# R7FA4W1AD register map
Vendor: Renesas; Series: RA4; File version: 1.0
CPU: CM4 r0p1, little endian, MPU, FPU, VTOR, 4 interrupt priority bits
Registers are 8-bit, read-write, reset 0x0 unless marked. A register's access mark holds for its fields unless they carry their own. Offsets are from the block's base; [hi:lo] are bit positions; {n}, {i} and the like mark numbered series.

## SYSTEM — System Control
Base 0x4001E000
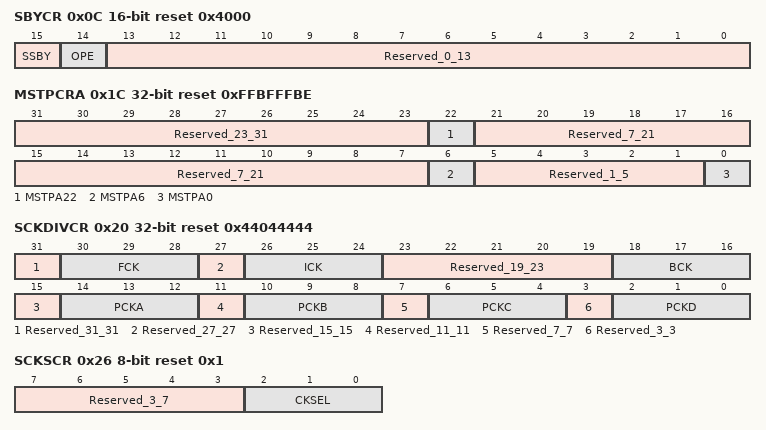
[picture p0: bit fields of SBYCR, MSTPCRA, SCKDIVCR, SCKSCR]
0x0C SBYCR 16-bit reset 0x4000 — Standby Control Register
  [15] SSBY — Software Standby
  [14] OPE — Output Port Enable
  [13:0] Reserved_0_13 — These bits are read as 00000000000000. The write value should be 00000000000000.
0x1C MSTPCRA 32-bit reset 0xFFBFFFBE — Module Stop Control Register A
  [31:23] Reserved_23_31 — These bits are read as 111111111. The write value should be 111111111.
  [22] MSTPA22 — DMA Controller/Data Transfer Controller Module Stop
  [21:7] Reserved_7_21 — These bits are read as 111111111111111. The write value should be 111111111111111.
  [6] MSTPA6 — ECCRAM Module Stop
  [5:1] Reserved_1_5 — These bits are read as 11111. The write value should be 11111.
  [0] MSTPA0 — RAM0 Module Stop
0x20 SCKDIVCR 32-bit reset 0x44044444 — System Clock Division Control Register
  [31] Reserved_31_31 — This bit is read as 0. The write value should be 0.
  [30:28] FCK — Flash IF Clock (FCLK) Select
  [27] Reserved_27_27 — This bit is read as 0. The write value should be 0.
  [26:24] ICK — System Clock (ICLK) Select
  [23:19] Reserved_19_23 — These bits are read as 00000. The write value should be 00000.
  [18:16] BCK — External Bus Clock (BCLK) Select
  [15] Reserved_15_15 — This bit is read as 0. The write value should be 0.
  [14:12] PCKA — Peripheral Module Clock A (PCLKA) Select
  [11] Reserved_11_11 — This bit is read as 0. The write value should be 0.
  [10:8] PCKB — Peripheral Module Clock B (PCLKB) Select
  [7] Reserved_7_7 — This bit is read as 0. The write value should be 0.
  [6:4] PCKC — Peripheral Module Clock C (PCLKC) Select
  [3] Reserved_3_3 — This bit is read as 0. The write value should be 0.
  [2:0] PCKD — Peripheral Module Clock D (PCLKD) Select
0x26 SCKSCR reset 0x1 — System Clock Source Control Register
  [7:3] Reserved_3_7 — These bits are read as 00000. The write value should be 00000.
  [2:0] CKSEL — Clock Source SelectSelecting the system clock source faster than 32MHz(system clock source > 32MHz ) is prohibit when SCKDIVCR.ICK[2:0] bits select the division,by-1 and MEMWAIT.MEMWAIT =0.
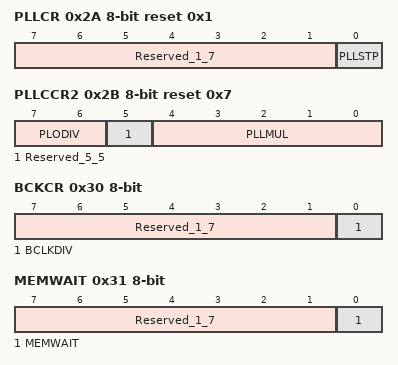
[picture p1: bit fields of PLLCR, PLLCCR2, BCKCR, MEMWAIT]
0x2A PLLCR reset 0x1 — PLL Control Register
  [7:1] Reserved_1_7 — These bits are read as 0000000. The write value should be 0000000.
  [0] PLLSTP — PLL Stop Control
0x2B PLLCCR2 reset 0x7 — PLL Clock Control Register2
  [7:6] PLODIV — PLL Output Frequency Division Ratio Select
  [5] Reserved_5_5 — This bit is read as 0. The write value should be 0.
  [4:0] PLLMUL — PLL Frequency Multiplication Factor Select
0x30 BCKCR — External Bus Clock Control Register
  [7:1] Reserved_1_7 — These bits are read as 0000000. The write value should be 0000000.
  [0] BCLKDIV — EBCLK Pin Output Select
0x31 MEMWAIT — Memory Wait Cycle Control Register
  [7:1] Reserved_1_7 — These bits are read as 0000000. The write value should be 0000000.
  [0] MEMWAIT — Memory Wait Cycle SelectNote: Writing 0 to the MEMWAIT is prohibited when SCKDIVCR.ICK selects division by 1 and SCKSCR.CKSEL[2:0] bits select thesystem clock source that is faster than 32 MHz (ICLK > 32 MHz).
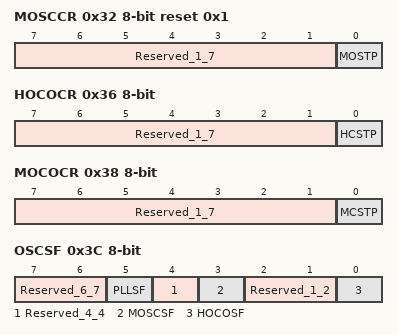
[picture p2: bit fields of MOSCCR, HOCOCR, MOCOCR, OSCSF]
0x32 MOSCCR reset 0x1 — Main Clock Oscillator Control Register
  [7:1] Reserved_1_7 — These bits are read as 0000000. The write value should be 0000000.
  [0] MOSTP — Main Clock Oscillator StopNote: MOMCR register must be set before setting MOSTP to 0.
0x36 HOCOCR (reset mask 0xFE) — High,Speed On,Chip Oscillator Control Register
  [7:1] Reserved_1_7 — These bits are read as 0000000. The write value should be 0000000.
  [0] HCSTP — HOCO Stop
0x38 MOCOCR — Middle,Speed On,Chip Oscillator Control Register
  [7:1] Reserved_1_7 — These bits are read as 0000000. The write value should be 0000000.
  [0] MCSTP — MOCO Stop
0x3C OSCSF ro (reset mask 0xFE) — Oscillation Stabilization Flag Register
  [7:6] Reserved_6_7 — These bits are read as 00.
  [5] PLLSF — PLL Clock Oscillation Stabilization Flag
  [4] Reserved_4_4 — This bit is read as 0.
  [3] MOSCSF — Main Clock Oscillation Stabilization Flag
  [2:1] Reserved_1_2 — These bits are read as 00.
  [0] HOCOSF — HOCO Clock Oscillation Stabilization FlagNOTE: The HOCOSF bit value after a reset is 1 when the OFS1.HOCOEN bit is 0. It is 0 when the OFS1.HOCOEN bit is 1.
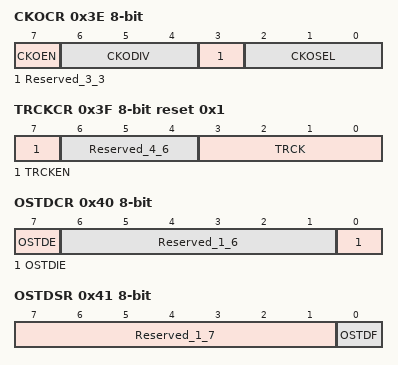
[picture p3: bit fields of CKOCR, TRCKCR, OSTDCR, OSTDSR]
0x3E CKOCR — Clock Out Control Register
  [7] CKOEN — Clock out enable
  [6:4] CKODIV — Clock out input frequency Division Select
  [3] Reserved_3_3 — This bit is read as 0. The write value should be 0.
  [2:0] CKOSEL — Clock out source select
0x3F TRCKCR reset 0x1 — Trace Clock Control Register
  [7] TRCKEN — Trace Clock operating enable
  [6:4] Reserved_4_6 — These bits are read as 000. The write value should be 000.
  [3:0] TRCK — Trace Clock operating frequency select
0x40 OSTDCR — Oscillation Stop Detection Control Register
  [7] OSTDE — Oscillation Stop Detection Function Enable
  [6:1] Reserved_1_6 — These bits are read as 000000. The write value should be 000000.
  [0] OSTDIE — Oscillation Stop Detection Interrupt Enable
0x41 OSTDSR — Oscillation Stop Detection Status Register
  [7:1] Reserved_1_7 — These bits are read as 0000000. The write value should be 0000000.
  [0] OSTDF write-0-clears read-modifies — Oscillation Stop Detection Flag
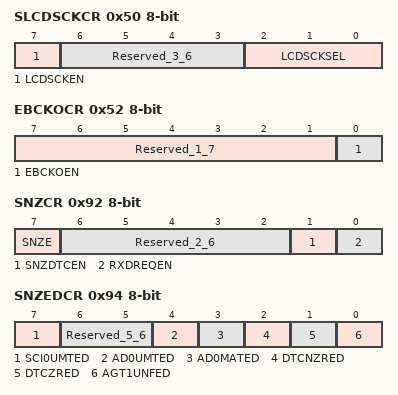
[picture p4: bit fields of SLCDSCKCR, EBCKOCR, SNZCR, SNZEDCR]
0x50 SLCDSCKCR — Segment LCD Source Clock Control Register
  [7] LCDSCKEN — LCD Source Clock Out Enable
  [6:3] Reserved_3_6 — These bits are read as 0000. The write value should be 0000.
  [2:0] LCDSCKSEL — LCD Source Clock (LCDSRCCLK) Select
0x52 EBCKOCR — External Bus Clock Output Control Register
  [7:1] Reserved_1_7 — These bits are read as 0000000. The write value should be 0000000.
  [0] EBCKOEN — EBCLK Pin Output Control
0x61 MOCOUTCR — MOCO User Trimming Control Register
  [7:0] MOCOUTRM — MOCO User Trimming 1000_0000 : -128 1000_0001 : -127 1000_0010 : -126 . . . 1111_1111 : -1 0000_0000 : Center Code 0000_0001 : +1 . . . 0111_1101 : +125 0111_1110 : +126 0111_1111 : +127These bits are added to original MOCO trimming bits
0x62 HOCOUTCR — HOCO User Trimming Control Register
  [7:0] HOCOUTRM — HOCO User Trimming 1000_0000 : -128 1000_0001 : -127 1000_0010 : -126 . . . 1111_1111 : -1 0000_0000 : Center Code 0000_0001 : +1 . . . 0111_1101 : +125 0111_1110 : +126 0111_1111 : +127These bits are added to original HOCO trimming bits
0x92 SNZCR — Snooze Control Register
  [7] SNZE — Snooze Mode Enable
  [6:2] Reserved_2_6 — These bits are read as 00000. The write value should be 00000.
  [1] SNZDTCEN — DTC Enable in Snooze Mode
  [0] RXDREQEN — RXD0 Snooze Request Enable NOTE: Do not set to 1 other than in asynchronous mode.
0x94 SNZEDCR — Snooze End Control Register
  [7] SCI0UMTED — SCI0 Address Mismatch Snooze End Enable
  [6:5] Reserved_5_6 — These bits are read as 00. The write value should be 00.
  [4] AD0UMTED — ADC140 Compare Mismatch Snooze End Enable
  [3] AD0MATED — ADC140 Compare Match Snooze End Enable
  [2] DTCNZRED — Not Last DTC Transmission Completion Snooze End Enable
  [1] DTCZRED — Last DTC Transmission Completion Snooze End Enable
  [0] AGT1UNFED — AGT1 Underflow Snooze End Enable
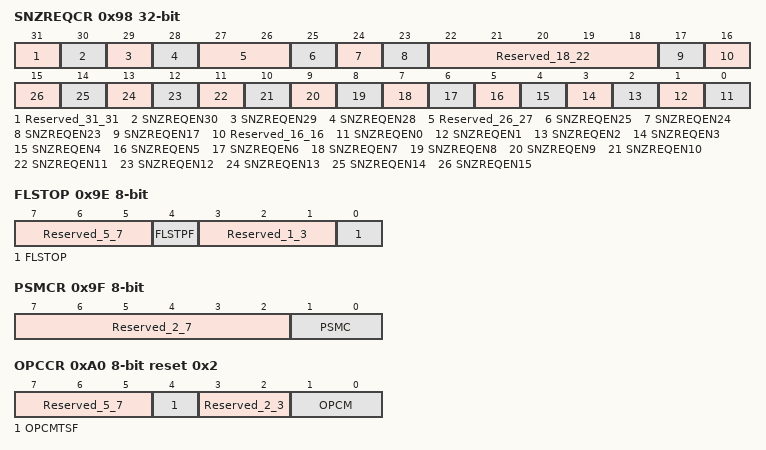
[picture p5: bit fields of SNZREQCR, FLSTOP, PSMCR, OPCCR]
0x98 SNZREQCR 32-bit — Snooze Request Control Register
  [31] Reserved_31_31 — This bit is read as 0. The write value should be 0.
  [30] SNZREQEN30 — Snooze Request Enable 30Enable AGT1 compare match B snooze request
  [29] SNZREQEN29 — Snooze Request Enable 29Enable AGT1 compare match A snooze request
  [28] SNZREQEN28 — Snooze Request Enable 28Enable AGT1 underflow snooze request
  [27:26] Reserved_26_27 — These bits are read as 00. The write value should be 00.
  [25] SNZREQEN25 — Snooze Request Enable 25Enable RTC period snooze request
  [24] SNZREQEN24 — Snooze Request Enable 24Enable RTC alarm snooze request
  [23] SNZREQEN23 — Snooze Request Enable 23Enable RTC alarm snooze request
  [22:18] Reserved_18_22 — These bits are read as 00000. The write value should be 00000.
  [17] SNZREQEN17 — Snooze Request Enable 17Enable KR snooze request
  [16] Reserved_16_16 — This bit is read as 0. The write value should be 0.
  [n] SNZREQEN{n} (n=0..15) — Snooze Request Enable {n}Enable IRQ{n} pin snooze request
0x9E FLSTOP — Flash Operation Control Register
  [7:5] Reserved_5_7 — These bits are read as 000. The write value should be 000.
  [4] FLSTPF — Flash Memory Operation Status Flag
  [3:1] Reserved_1_3 — These bits are read as 000. The write value should be 000.
  [0] FLSTOP — Selecting ON/OFF of the Flash Memory Operation
0x9F PSMCR — Power Save Memory Control Register
  [7:2] Reserved_2_7 — These bits are read as 000000. The write value should be 000000.
  [1:0] PSMC — Power save memory control.
0xA0 OPCCR reset 0x2 — Operating Power Control Register
  [7:5] Reserved_5_7 — These bits are read as 000. The write value should be 000.
  [4] OPCMTSF — Operating Power Control Mode Transition Status Flag
  [3:2] Reserved_2_3 — These bits are read as 00. The write value should be 00.
  [1:0] OPCM — Operating Power Control Mode Select
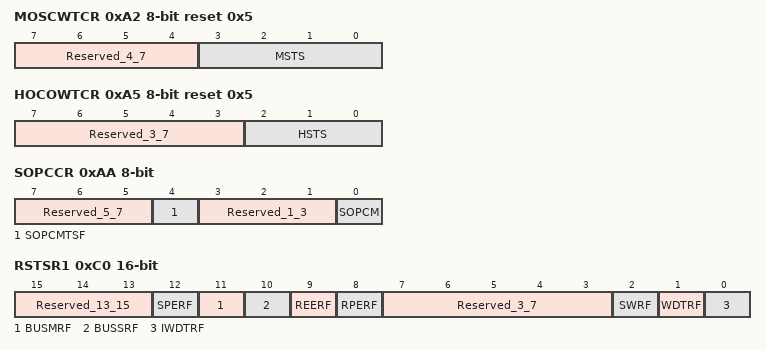
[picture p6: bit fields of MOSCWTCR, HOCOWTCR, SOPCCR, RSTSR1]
0xA2 MOSCWTCR reset 0x5 — Main Clock Oscillator Wait Control Register
  [7:4] Reserved_4_7 — These bits are read as 0000. The write value should be 0000.
  [3:0] MSTS — Main clock oscillator wait time setting
0xA5 HOCOWTCR reset 0x5 — High,Speed On,Chip Oscillator Wait Control Register
  [7:3] Reserved_3_7 — These bits are read as 00000. The write value should be 00000.
  [2:0] HSTS — HOCO wait time setting
0xAA SOPCCR — Sub Operating Power Control Register
  [7:5] Reserved_5_7 — These bits are read as 000. The write value should be 000.
  [4] SOPCMTSF ro — Sub Operating Power Control Mode Transition Status Flag
  [3:1] Reserved_1_3 — These bits are read as 000. The write value should be 000.
  [0] SOPCM — Sub Operating Power Control Mode Select
0xC0 RSTSR1 16-bit (reset mask 0xE0F8) — Reset Status Register 1
  [15:13] Reserved_13_15 — These bits are read as 000. The write value should be 000.
  [12] SPERF write-0-clears read-modifies — SP Error Reset Detect FlagNote: Only 0 can be written to clear the flag. The reset flag must be written as 0 after the reset flag is read as 1.
  [11] BUSMRF write-0-clears read-modifies — Bus Master MPU Reset Detect FlagNote: Only 0 can be written to clear the flag. The reset flag must be written as 0 after the reset flag is read as 1.
  [10] BUSSRF write-0-clears read-modifies — Bus Slave MPU Reset Detect FlagNote: Only 0 can be written to clear the flag. The reset flag must be written as 0 after the reset flag is read as 1.
  [9] REERF write-0-clears read-modifies — RAM ECC Error Reset Detect FlagNote: Only 0 can be written to clear the flag. The reset flag must be written as 0 after the reset flag is read as 1.
  [8] RPERF write-0-clears read-modifies — RAM Parity Error Reset Detect FlagNote: Only 0 can be written to clear the flag. The reset flag must be written as 0 after the reset flag is read as 1.
  [7:3] Reserved_3_7 — These bits are read as 00000. The write value should be 00000.
  [2] SWRF write-0-clears read-modifies — Software Reset Detect FlagNote: Only 0 can be written to clear the flag. The reset flag must be written as 0 after the reset flag is read as 1.
  [1] WDTRF write-0-clears read-modifies — Watchdog Timer Reset Detect FlagNote: Only 0 can be written to clear the flag. The reset flag must be written as 0 after the reset flag is read as 1.
  [0] IWDTRF write-0-clears read-modifies — Independent Watchdog Timer Reset Detect FlagNote: Only 0 can be written to clear the flag. The reset flag must be written as 0 after the reset flag is read as 1.
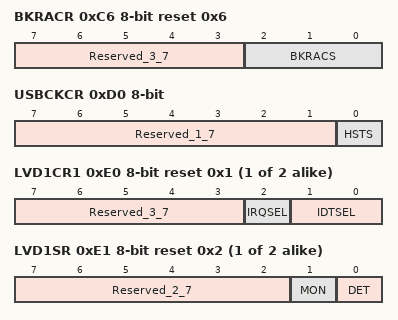
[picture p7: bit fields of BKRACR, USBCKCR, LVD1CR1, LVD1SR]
0xC6 BKRACR reset 0x6 — Backup Register Access Control Register
  [7:3] Reserved_3_7 — These bits are read as 00000. The write value should be 00000.
  [2:0] BKRACS — Backup Register Access Control Register
0xD0 USBCKCR — USB Clock Control register
  [7:1] Reserved_1_7 — These bits are read as 0000000. The write value should be 0000000.
  [0] HSTS — USB Clock Source Select
{0xDE+2i} LVD{i}CR1 (i=1..2) reset 0x1 — Voltage Monitor {i} Circuit Control Register 1
  [7:3] Reserved_3_7 — These bits are read as 00000. The write value should be 00000.
  [2] IRQSEL — Voltage Monitor Interrupt Type Select
  [1:0] IDTSEL — Voltage Monitor Interrupt Generation Condition Select
{0xDF+2i} LVD{i}SR (i=1..2) reset 0x2 — Voltage Monitor {i} Circuit Status Register
  [7:2] Reserved_2_7 — These bits are read as 000000. The write value should be 000000.
  [1] MON ro — Voltage Monitor 1 Signal Monitor Flag
  [0] DET write-0-clears read-modifies — Voltage Monitor Voltage Change Detection Flag NOTE: Only 0 can be written to this bit. After writing 0 to this bit, it takes 2 system clock cycles for the bit to be read as 0.
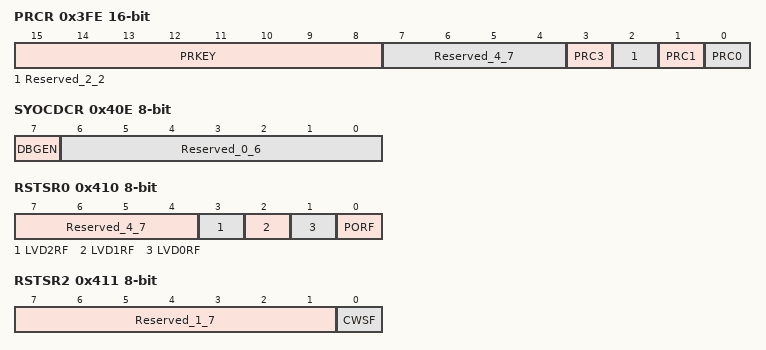
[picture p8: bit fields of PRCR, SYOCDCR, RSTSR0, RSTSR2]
0x3FE PRCR 16-bit — Protect Register
  [15:8] PRKEY wo — PRC Key Code
  [7:4] Reserved_4_7 — These bits are read as 0000. The write value should be 0000.
  [3] PRC3 — Protect Bit 3
  [2] Reserved_2_2 — This bit is read as 0. The write value should be 0.
  [1] PRC1 — Protect Bit 1
  [0] PRC0 — Protect Bit 0
0x40E SYOCDCR — System Control OCD Control Register
  [7] DBGEN — Debugger Enable bit
  [6:0] Reserved_0_6 — These bits are read as 0000000. The write value should be 0000000.
0x410 RSTSR0 (reset mask 0xF0) — Reset Status Register 0
  [7:4] Reserved_4_7 — These bits are read as 0000. The write value should be 0000.
  [3] LVD2RF write-0-clears read-modifies — Voltage Monitor 2 Reset Detect FlagNote: Only 0 can be written to clear the flag. The reset flag must be written with 0 after the reset flag is read as 1.
  [2] LVD1RF write-0-clears read-modifies — Voltage Monitor 1 Reset Detect FlagNote: Only 0 can be written to clear the flag. The reset flag must be written with 0 after the reset flag is read as 1.
  [1] LVD0RF write-0-clears read-modifies — Voltage Monitor 0 Reset Detect FlagNote: Only 0 can be written to clear the flag. The reset flag must be written with 0 after the reset flag is read as 1.
  [0] PORF write-0-clears read-modifies — Power,On Reset Detect FlagNote: Only 0 can be written to clear the flag. The reset flag must be written with 0 after the reset flag is read as 1.
0x411 RSTSR2 (reset mask 0xFE) — Reset Status Register 2
  [7:1] Reserved_1_7 — These bits are read as 0000000. The write value should be 0000000.
  [0] CWSF write-1-sets read-modifies — Cold/Warm Start Determination FlagNote: Only 1 can be written to set the flag.
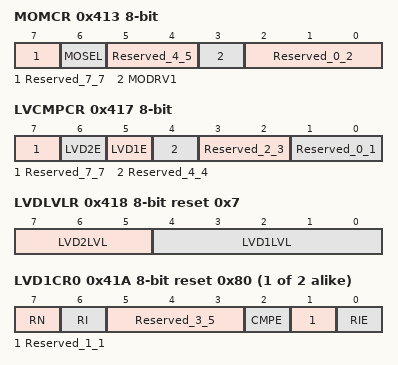
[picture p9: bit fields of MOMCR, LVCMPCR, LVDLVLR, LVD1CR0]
0x413 MOMCR — Main Clock Oscillator Mode Oscillation Control Register
  [7] Reserved_7_7 — This bit is read as 0. The write value should be 0.
  [6] MOSEL — Main Clock Oscillator Switching
  [5:4] Reserved_4_5 — These bits are read as 00. The write value should be 00.
  [3] MODRV1 — Main Clock Oscillator Drive Capability 1 Switching
  [2:0] Reserved_0_2 — These bits are read as 000. The write value should be 000.
0x417 LVCMPCR — Voltage Monitor Circuit Control Register
  [7] Reserved_7_7 — This bit is read as 0. The write value should be 0.
  [6] LVD2E — Voltage Detection 2 Enable
  [5] LVD1E — Voltage Detection 1 Enable
  [4] Reserved_4_4 — This bit is read as 0. The write value should be 0.
  [3:2] Reserved_2_3 — These bits are read as 00. The write value should be 00.
  [1:0] Reserved_0_1 — These bits are read as 00. The write value should be 00.
0x418 LVDLVLR reset 0x7 — Voltage Detection Level Select Register
  [7:5] LVD2LVL — Voltage Detection 2 Level Select (Standard voltage during drop in voltage)
  [4:0] LVD1LVL — Voltage Detection 1 Level Select (Standard voltage during drop in voltage)
{0x419+i} LVD{i}CR0 (i=1..2) reset 0x80 (reset mask 0xF7) — Voltage Monitor {i} Circuit Control Register 0
  [7] RN — Voltage Monitor Reset Negate Select
  [6] RI — Voltage Monitor Circuit Mode Select
  [5:3] Reserved_3_5 — These bits are read as 000. The write value should be 000.
  [2] CMPE — Voltage Monitor Circuit Comparison Result Output Enable
  [1] Reserved_1_1 — This bit is read as 0. The write value should be 0.
  [0] RIE — Voltage Monitor Interrupt/Reset Enable
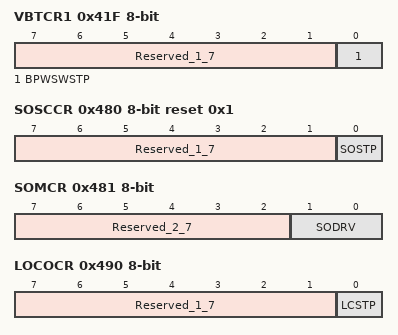
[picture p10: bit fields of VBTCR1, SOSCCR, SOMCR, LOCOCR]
0x41F VBTCR1 — VBATT Control Register1
  [7:1] Reserved_1_7 — These bits are read as 0000000. The write value should be 0000000.
  [0] BPWSWSTP — Battery Power supply Switch Stop
0x480 SOSCCR reset 0x1 — Sub,Clock Oscillator Control Register
  [7:1] Reserved_1_7 — These bits are read as 0000000. The write value should be 0000000.
  [0] SOSTP — Sub,Clock Oscillator Stop
0x481 SOMCR — Sub Clock Oscillator Mode Control Register
  [7:2] Reserved_2_7 — These bits are read as 000000. The write value should be 000000.
  [1:0] SODRV — Sub,Clock Oscillator Drive Capability Switching
0x490 LOCOCR — Low,Speed On,Chip Oscillator Control Register
  [7:1] Reserved_1_7 — These bits are read as 0000000. The write value should be 0000000.
  [0] LCSTP — LOCO Stop
0x492 LOCOUTCR — LOCO User Trimming Control Register
  [7:0] LOCOUTRM — LOCO User Trimming 1000_0000 : -128 1000_0001 : -127 1000_0010 : -126 . . . 1111_1111 : -1 0000_0000 : Center Code 0000_0001 : +1 . . . 0111_1101 : +125 0111_1110 : +126 0111_1111 : +127These bits are added to original LOCO trimming bits
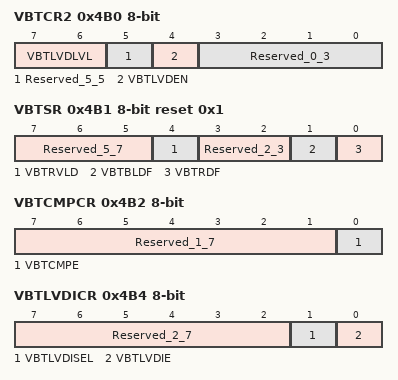
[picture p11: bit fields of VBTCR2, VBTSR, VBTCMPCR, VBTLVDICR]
0x4B0 VBTCR2 — VBATT Control Register2
  [7:6] VBTLVDLVL — VBATT Pin Voltage Low Voltage Detect Level Select Bit
  [5] Reserved_5_5 — This bit is read as 0. The write value should be 0.
  [4] VBTLVDEN — VBATT Pin Low Voltage Detect Enable Bit
  [3:0] Reserved_0_3 — These bits are read as 0000. The write value should be 0000.
0x4B1 VBTSR reset 0x1 (reset mask 0xEC) — VBATT Status Register
  [7:5] Reserved_5_7 — These bits are read as 000. The write value should be 000.
  [4] VBTRVLD ro — VBATT_R Valid
  [3:2] Reserved_2_3 — These bits are read as 00. The write value should be 00.
  [1] VBTBLDF write-0-clears read-modifies — VBATT Battery Low voltage Detect Flag
  [0] VBTRDF write-0-clears read-modifies — VBAT_R Reset Detect Flag
0x4B2 VBTCMPCR — VBATT Comparator Control Register
  [7:1] Reserved_1_7 — These bits are read as 0000000. The write value should be 0000000.
  [0] VBTCMPE — VBATT pin low voltage detect circuit output enable
0x4B4 VBTLVDICR — VBATT Pin Low Voltage Detect Interrupt Control Register
  [7:2] Reserved_2_7 — These bits are read as 000000. The write value should be 000000.
  [1] VBTLVDISEL — Pin Low Voltage Detect Interrupt Select bit
  [0] VBTLVDIE — VBATT Pin Low Voltage Detect Interrupt Enable bit
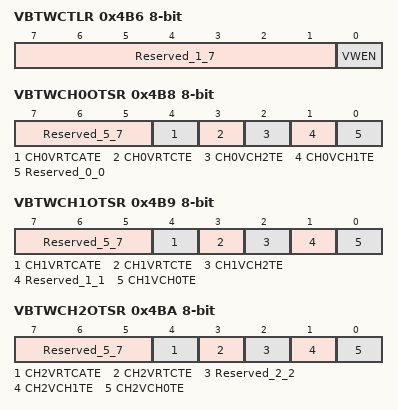
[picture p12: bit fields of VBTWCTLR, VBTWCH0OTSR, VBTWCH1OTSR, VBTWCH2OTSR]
0x4B6 VBTWCTLR — VBATT Wakeup function Control Register
  [7:1] Reserved_1_7 — These bits are read as 0000000. The write value should be 0000000.
  [0] VWEN — VBATT wakeup enable
0x4B8 VBTWCH0OTSR — VBATT Wakeup I/O 0 Output Trigger Select Register
  [7:5] Reserved_5_7 — These bits are read as 000. The write value should be 000.
  [4] CH0VRTCATE — VBATWIO0 Output RTC Alarm Signal Enable
  [3] CH0VRTCTE — VBATWIO0 Output RTC Periodic Signal Enable
  [2] CH0VCH2TE — VBATWIO0 Output VBATWIO2 Trigger Enable
  [1] CH0VCH1TE — VBATWIO0 Output VBATWIO1 Trigger Enable
  [0] Reserved_0_0 — This bit is read as 0. The write value should be 0.
0x4B9 VBTWCH1OTSR — VBATT Wakeup I/O 1 Output Trigger Select Register
  [7:5] Reserved_5_7 — These bits are read as 000. The write value should be 000.
  [4] CH1VRTCATE — VBATWIO1 Output RTC Alarm Signal Enable
  [3] CH1VRTCTE — VBATWIO1 Output RTC Periodic Signal Enable
  [2] CH1VCH2TE — VBATWIO1 Output VBATWIO2 Trigger Enable
  [1] Reserved_1_1 — This bit is read as 0. The write value should be 0.
  [0] CH1VCH0TE — VBATWIO1 Output VBATWIO0 Trigger Enable
0x4BA VBTWCH2OTSR — VBATT Wakeup I/O 2 Output Trigger Select Register
  [7:5] Reserved_5_7 — These bits are read as 000. The write value should be 000.
  [4] CH2VRTCATE — VBATWIO2 Output RTC Alarm Signal Enable
  [3] CH2VRTCTE — VBATWIO2 Output RTC Periodic Signal Enable
  [2] Reserved_2_2 — This bit is read as 0. The write value should be 0.
  [1] CH2VCH1TE — VBATWIO2 Output VBATWIO1 Trigger Enable
  [0] CH2VCH0TE — VBATWIO2 Output VBATWIO0 Trigger Enable
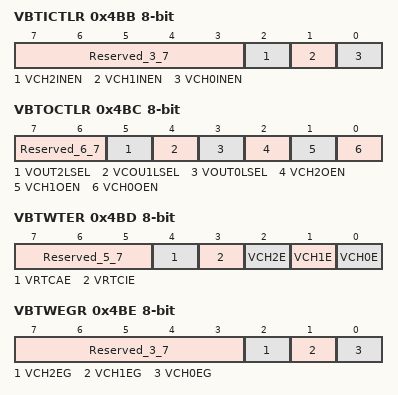
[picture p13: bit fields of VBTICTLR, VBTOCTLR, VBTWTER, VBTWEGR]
0x4BB VBTICTLR — VBATT Input Control Register
  [7:3] Reserved_3_7 — These bits are read as 00000. The write value should be 00000.
  [2] VCH2INEN — VBATT Wakeup I/O 2 Input Enable
  [1] VCH1INEN — VBATT Wakeup I/O 1 Input Enable
  [0] VCH0INEN — VBATT Wakeup I/O 0 Input Enable
0x4BC VBTOCTLR — VBATT Output Control Register
  [7:6] Reserved_6_7 — These bits are read as 00. The write value should be 00.
  [5] VOUT2LSEL — VBATT Wakeup I/O 2 Output Level Selection
  [4] VCOU1LSEL — VBATT Wakeup I/O 1 Output Level Selection
  [3] VOUT0LSEL — VBATT Wakeup I/O 0 Output Level Selection
  [2] VCH2OEN — VBATT Wakeup I/O 2 Output Enable
  [1] VCH1OEN — VBATT Wakeup I/O 1 Output Enable
  [0] VCH0OEN — VBATT Wakeup I/O 0 Output Enable
0x4BD VBTWTER — VBATT Wakeup Trigger source Enable Register
  [7:5] Reserved_5_7 — These bits are read as 000. The write value should be 000.
  [4] VRTCAE — RTC Alarm Signal Enable
  [3] VRTCIE — RTC Periodic Signal Enable
  [2] VCH2E — VBATWIO2 Pin Enable
  [1] VCH1E — VBATWIO1 Pin Enable
  [0] VCH0E — VBATWIO0 Pin Enable
0x4BE VBTWEGR — VBATT Wakeup Trigger source Edge Register
  [7:3] Reserved_3_7 — These bits are read as 00000. The write value should be 00000.
  [2] VCH2EG — VBATWIO2 Wakeup Trigger Source Edge Select
  [1] VCH1EG — VBATWIO1 Wakeup Trigger Source Edge Select
  [0] VCH0EG — VBATWIO0 Wakeup Trigger Source Edge Select
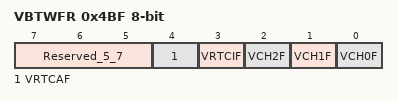
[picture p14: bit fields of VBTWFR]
0x4BF VBTWFR — VBATT Wakeup trigger source Flag Register
  [7:5] Reserved_5_7 — These bits are read as 000. The write value should be 000.
  [4] VRTCAF write-0-clears read-modifies — VBATT RTC,Alarm Wakeup Trigger Flag
  [3] VRTCIF write-0-clears read-modifies — VBATT RTC,Interval Wakeup Trigger Flag
  [2] VCH2F write-0-clears read-modifies — VBATWIO2 Wakeup Trigger Flag
  [1] VCH1F write-0-clears read-modifies — VBATWIO1 Wakeup Trigger Flag
  [0] VCH0F write-0-clears read-modifies — VBATWIO0 Wakeup Trigger Flag
{0x500+i} VBTBKR[{i}] (i=0..511) reset not defined — VBATT Backup Register [{i}]
  [7:0] VBTBKR — VBTBKR is a 512-byte readable/writable register to store data powered by VBATT.The value of this register is retained even when VCC is not powered but VBATT is powered.VBTBKR is initialized by VBATT selected voltage power,on,reset.
